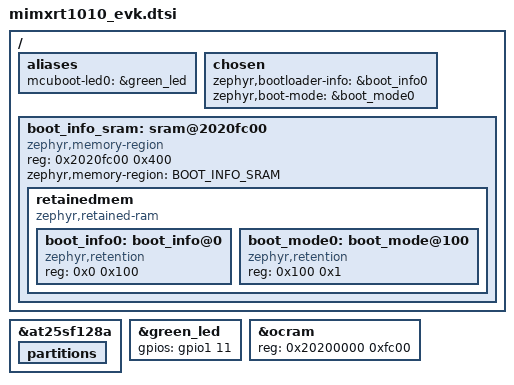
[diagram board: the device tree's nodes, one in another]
/* Board-specific overlay glue for mimxrt1010_evk.
 *
 * Hand-maintained: device enablement (status = "okay"), delete-nodes
 * for partitions that must be replaced, aliases and chosen nodes. The
 * flash partition layout lives in mimxrt1010_evk-partitions.dtsi, which is
 * generated by tools/partition_layout.py --fix and included below.
 */

/* Delete the storage partition so we can replace it with nvm + filesystem,
 * and the image-1 partition, which this single-app layout does not use and
 * which would otherwise overlap the filesystem. */
&at25sf128a {
	partitions {
		/delete-node/ partition@720000;
		/delete-node/ partition@e20000;
	};
};

/* Bootloader UI: the entrance button comes from the board's
 * mcuboot-button0 alias (the user button). Point mcuboot-led0 at the
 * green LED so a CONFIG_MCUBOOT_INDICATION_LED build has a status LED.
 *
 * The upstream board dts declares the LED (D25, User LD1) active low, but
 * on the board it lights when GPIO_11 is high. */
&green_led {
	gpios = <&gpio1 11 GPIO_ACTIVE_HIGH>;
};

/ {
	aliases {
		mcuboot-led0 = &green_led;
	};
};

#include "mimxrt1010_evk-partitions.dtsi"

/* Bootloader info shared-data area: the last KB of OCRAM, kept out of the
 * managed RAM so neither image clobbers it. The bootloader writes its boot
 * state here on every boot (BOOT_SHARE_DATA_BOOTINFO -> BLINFO TLVs via
 * boot_write_shared_data()); the application reads the same region to
 * answer the SMP bootloader-info command (RETENTION_BOOTLOADER_INFO_TYPE_
 * MCUBOOT). Carved here because this dtsi applies to both images.
 *
 * A second, one-byte retention cell in the same block backs the boot-mode
 * flag (zephyr,boot-mode): the application sets it to request the
 * bootloader's update mode (reset_to_bootloader() / RunMode.UF2) and the
 * bootloader reads and clears it at boot (io_detect_boot_mode()).
 *
 * The flag has to survive the boot ROM, which runs again on the warm
 * reset that follows the request. The ROM's own data and stack occupy
 * only 0x2020_0000-0x2020_57FF (IMXRT1010RM 9.5.1), and Zephyr does not
 * repartition this board's default FlexRAM split (64 KB OCRAM), so this
 * block keeps its contents across SYSRESETREQ. A power cycle simply drops
 * the request.
 */
&ocram {
	reg = <0x20200000 0xfc00>;
};

/ {
	chosen {
		zephyr,bootloader-info = &boot_info0;
		zephyr,boot-mode = &boot_mode0;
	};

	boot_info_sram: sram@2020fc00 {
		compatible = "zephyr,memory-region", "mmio-sram";
		reg = <0x2020fc00 0x400>;
		zephyr,memory-region = "BOOT_INFO_SRAM";
		status = "okay";

		retainedmem {
			compatible = "zephyr,retained-ram";
			status = "okay";
			#address-cells = <1>;
			#size-cells = <1>;

			boot_info0: boot_info@0 {
				compatible = "zephyr,retention";
				status = "okay";
				reg = <0x0 0x100>;
			};

			boot_mode0: boot_mode@100 {
				compatible = "zephyr,retention";
				status = "okay";
				reg = <0x100 0x1>;
			};
		};
	};
};
